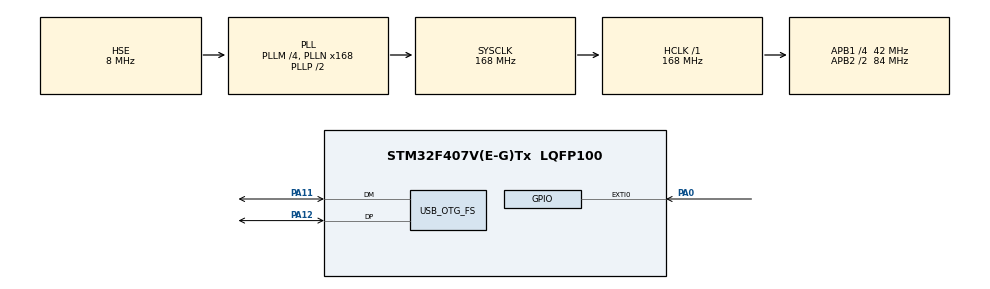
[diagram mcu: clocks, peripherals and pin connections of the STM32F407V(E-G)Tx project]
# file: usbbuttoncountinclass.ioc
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Mcu.Family=STM32F4
Mcu.Name=STM32F407V(E-G)Tx
Mcu.Package=LQFP100
NVIC.EXTI0_IRQn=true\:0\:0\:false\:false\:true\:true\:true\:true
NVIC.OTG_FS_IRQn=true\:0\:0\:false\:false\:true\:false\:true\:true
NVIC.PriorityGroup=NVIC_PRIORITYGROUP_0
NVIC.TIM2_IRQn=true\:0\:0\:false\:false\:true\:true\:true\:true
PA0-WKUP.GPIO_ModeDefaultEXTI=GPIO_MODE_IT_RISING_FALLING
PA0-WKUP.Signal=GPXTI0
PA11.Mode=Device_Only
PA11.Signal=USB_OTG_FS_DM
PA12.Mode=Device_Only
PA12.Signal=USB_OTG_FS_DP
PA13.Mode=Trace_Asynchronous_SW
PA13.Signal=SYS_JTMS-SWDIO
PA14.Mode=Trace_Asynchronous_SW
PA14.Signal=SYS_JTCK-SWCLK
PB3.Mode=Trace_Asynchronous_SW
PB3.Signal=SYS_JTDO-SWO
PH0-OSC_IN.Mode=HSE-External-Oscillator
PH0-OSC_IN.Signal=RCC_OSC_IN
PH1-OSC_OUT.Mode=HSE-External-Oscillator
PH1-OSC_OUT.Signal=RCC_OSC_OUT
ProjectManager.HeapSize=0x200
ProjectManager.StackSize=0x400
ProjectManager.TargetToolchain=STM32CubeIDE
RCC.48MHZClocksFreq_Value=48000000
RCC.AHBFreq_Value=168000000
RCC.APB1CLKDivider=RCC_HCLK_DIV4
RCC.APB1Freq_Value=42000000
RCC.APB1TimFreq_Value=84000000
RCC.APB2CLKDivider=RCC_HCLK_DIV2
RCC.APB2Freq_Value=84000000
RCC.APB2TimFreq_Value=168000000
RCC.CortexFreq_Value=168000000
RCC.HCLKFreq_Value=168000000
RCC.HSE_VALUE=8000000
RCC.HSI_VALUE=16000000
RCC.LSE_VALUE=32768
RCC.PLLM=4
RCC.PLLN=168
RCC.PLLQ=7
RCC.SYSCLKFreq_VALUE=168000000
RCC.SYSCLKSource=RCC_SYSCLKSOURCE_PLLCLK
RCC.VCOOutputFreq_Value=336000000
TIM2.Period=800-1
TIM2.Prescaler=42000-1
USB_DEVICE.CLASS_NAME_FS=CDC
USB_DEVICE.VirtualMode-CDC_FS=Cdc
USB_DEVICE.VirtualModeFS=Cdc_FS
USB_OTG_FS.VirtualMode=Device_Only
VP_TIM2_VS_ClockSourceINT.Mode=Internal
VP_USB_DEVICE_VS_USB_DEVICE_CDC_FS.Mode=CDC_FS
board=STM32F407G-DISC1

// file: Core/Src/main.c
/* USER CODE BEGIN Header */
/**
  ******************************************************************************
  * @file           : main.c
  * @brief          : Main program body
  ******************************************************************************
  * @attention
  *
  * Copyright (c) 2022 STMicroelectronics.
  * All rights reserved.
  *
  * This software is licensed under terms that can be found in the LICENSE file
  * in the root directory of this software component.
  * If no LICENSE file comes with this software, it is provided AS-IS.
  *
  ******************************************************************************
  */
/* USER CODE END Header */
#include "main.h"
#include "usb_device.h"

/* USER CODE BEGIN Includes */
static enum
  		{
  	idle,
  	bdown,
  	bup
  		}state=idle;
/* USER CODE END Includes */

/* USER CODE BEGIN PTD */
uint32_t buttonupcount=0;
uint32_t buttondowncount=0;
uint32_t timercount;
/* USER CODE END PTD */

TIM_HandleTypeDef htim2;

void SystemClock_Config(void);
static void MX_GPIO_Init(void);
static void MX_TIM2_Init(void);

int main(void)
{
  /* USER CODE BEGIN 1 */
timercount=TIM2->CNT;
  /* USER CODE END 1 */

  /* MCU Configuration--------------------------------------------------------*/

  /* Reset of all peripherals, Initializes the Flash interface and the Systick. */
  HAL_Init();

  /* Configure the system clock */
  SystemClock_Config();

  /* Initialize all configured peripherals */
  MX_GPIO_Init();
  MX_USB_DEVICE_Init();
  MX_TIM2_Init();

  /* Infinite loop */
  while (1)
  {

  }
}

void SystemClock_Config(void)
{
  RCC_OscInitTypeDef RCC_OscInitStruct = {0};
  RCC_ClkInitTypeDef RCC_ClkInitStruct = {0};

  /** Configure the main internal regulator output voltage
  */
  __HAL_RCC_PWR_CLK_ENABLE();
  __HAL_PWR_VOLTAGESCALING_CONFIG(PWR_REGULATOR_VOLTAGE_SCALE1);

  /** Initializes the RCC Oscillators according to the specified parameters
  * in the RCC_OscInitTypeDef structure.
  */
  RCC_OscInitStruct.OscillatorType = RCC_OSCILLATORTYPE_HSE;
  RCC_OscInitStruct.HSEState = RCC_HSE_ON;
  RCC_OscInitStruct.PLL.PLLState = RCC_PLL_ON;
  RCC_OscInitStruct.PLL.PLLSource = RCC_PLLSOURCE_HSE;
  RCC_OscInitStruct.PLL.PLLM = 4;
  RCC_OscInitStruct.PLL.PLLN = 168;
  RCC_OscInitStruct.PLL.PLLP = RCC_PLLP_DIV2;
  RCC_OscInitStruct.PLL.PLLQ = 7;
  if (HAL_RCC_OscConfig(&RCC_OscInitStruct) != HAL_OK)
  {
    Error_Handler();
  }

  /** Initializes the CPU, AHB and APB buses clocks
  */
  RCC_ClkInitStruct.ClockType = RCC_CLOCKTYPE_HCLK|RCC_CLOCKTYPE_SYSCLK
                              |RCC_CLOCKTYPE_PCLK1|RCC_CLOCKTYPE_PCLK2;
  RCC_ClkInitStruct.SYSCLKSource = RCC_SYSCLKSOURCE_PLLCLK;
  RCC_ClkInitStruct.AHBCLKDivider = RCC_SYSCLK_DIV1;
  RCC_ClkInitStruct.APB1CLKDivider = RCC_HCLK_DIV4;
  RCC_ClkInitStruct.APB2CLKDivider = RCC_HCLK_DIV2;

  if (HAL_RCC_ClockConfig(&RCC_ClkInitStruct, FLASH_LATENCY_5) != HAL_OK)
  {
    Error_Handler();
  }
}

static void MX_TIM2_Init(void)
{

  TIM_ClockConfigTypeDef sClockSourceConfig = {0};
  TIM_MasterConfigTypeDef sMasterConfig = {0};

  htim2.Instance = TIM2;
  htim2.Init.Prescaler = 42000-1;
  htim2.Init.CounterMode = TIM_COUNTERMODE_UP;
  htim2.Init.Period = 800-1;
  htim2.Init.ClockDivision = TIM_CLOCKDIVISION_DIV1;
  htim2.Init.AutoReloadPreload = TIM_AUTORELOAD_PRELOAD_DISABLE;
  if (HAL_TIM_Base_Init(&htim2) != HAL_OK)
  {
    Error_Handler();
  }
  sClockSourceConfig.ClockSource = TIM_CLOCKSOURCE_INTERNAL;
  if (HAL_TIM_ConfigClockSource(&htim2, &sClockSourceConfig) != HAL_OK)
  {
    Error_Handler();
  }
  sMasterConfig.MasterOutputTrigger = TIM_TRGO_RESET;
  sMasterConfig.MasterSlaveMode = TIM_MASTERSLAVEMODE_DISABLE;
  if (HAL_TIMEx_MasterConfigSynchronization(&htim2, &sMasterConfig) != HAL_OK)
  {
    Error_Handler();
  }

}

static void MX_GPIO_Init(void)
{
  GPIO_InitTypeDef GPIO_InitStruct = {0};

  /* GPIO Ports Clock Enable */
  __HAL_RCC_GPIOH_CLK_ENABLE();
  __HAL_RCC_GPIOA_CLK_ENABLE();
  __HAL_RCC_GPIOB_CLK_ENABLE();

  /*Configure GPIO pin : PA0 */
  GPIO_InitStruct.Pin = GPIO_PIN_0;
  GPIO_InitStruct.Mode = GPIO_MODE_IT_RISING_FALLING;
  GPIO_InitStruct.Pull = GPIO_NOPULL;
  HAL_GPIO_Init(GPIOA, &GPIO_InitStruct);

  /* EXTI interrupt init*/
  HAL_NVIC_SetPriority(EXTI0_IRQn, 0, 0);
  HAL_NVIC_EnableIRQ(EXTI0_IRQn);

}

/* USER CODE BEGIN 4 */
void HAL_GPIO_EXTI_Callback(uint16_t GPIO_Pin)
{
	if (GPIO_Pin==GPIO_PIN_0)
	{
		switch (HAL_GPIO_ReadPin(GPIOA, GPIO_PIN_0))
		{case 0:
			HAL_TIM_Base_Start_IT(&htim2);
			HAL_NVIC_DisableIRQ(EXTI0_IRQn);
			state=bup;
			buttonupcount++;

			break;

		case 1:

			state=bdown;
			buttondowncount++;

			break;

		}
		//HAL_NVIC_DisableIRQ(EXTI0_IRQn);

	}// if button
}//exti callback
void HAL_TIM_PeriodElapsedCallback(TIM_HandleTypeDef *htim)
{

	 state=idle;
	 HAL_TIM_Base_Stop_IT(&htim2);
	 HAL_NVIC_EnableIRQ(EXTI0_IRQn);

}//period callback

/* USER CODE END 4 */

void Error_Handler(void)
{
  __disable_irq();
  while (1)
  {
  }
}
